# M367 register map
File version: 0.1
CPU: 
Registers are 32-bit, read-write, reset 0x0 unless marked. A register's access mark holds for its fields unless they carry their own. Offsets are from the block's base; [hi:lo] are bit positions; {n}, {i} and the like mark numbered series; 'fields as' and 'values as' point back to an identical list.

## UDFS2 — UDC2(USB -Spec2.0 Device contoller)
Base 0x40008200
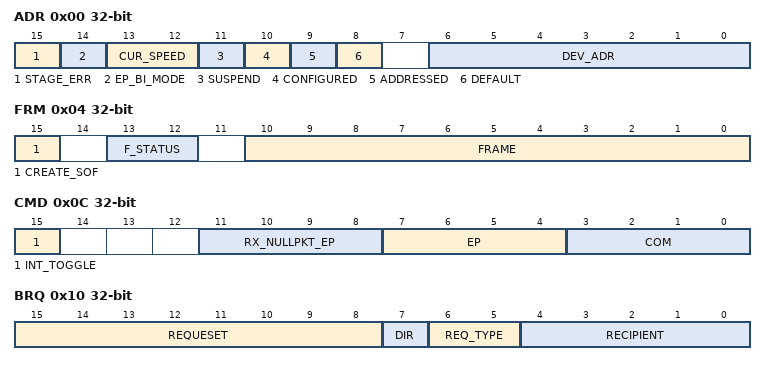
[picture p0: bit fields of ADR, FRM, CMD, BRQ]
0x00 ADR — UDC2 Address State
  [15] STAGE_ERR, [14] EP_BI_MODE, [13:12] CUR_SPEED ro, [11] SUSPEND ro, [10] CONFIGURED, [9] ADDRESSED, [8] DEFAULT, [6:0] DEV_ADR
0x04 FRM — UDC2 Frame
  [15] CREATE_SOF, [13:12] F_STATUS ro, [10:0] FRAME ro
0x0C CMD — UDC2 Command
  [15] INT_TOGGLE, [11:8] RX_NULLPKT_EP ro, [7:4] EP, [3:0] COM
0x10 BRQ ro — UDC2 bRequest-bmRequest Type
  [15:8] REQUESET, [7] DIR, [6:5] REQ_TYPE, [4:0] RECIPIENT
0x14 WVL ro — UDC2 wValue
  [15:0] VALUE
0x18 WIDX ro — UDC2 wIndex
  [15:0] INDEX
0x1C WLGTH ro — UDC2 wLength
  [15:0] LENGTH
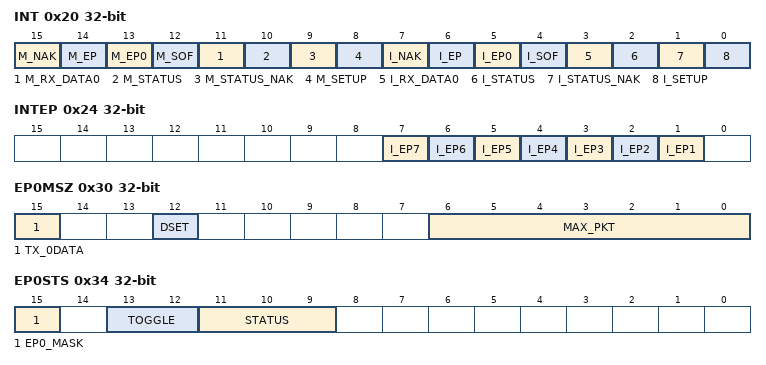
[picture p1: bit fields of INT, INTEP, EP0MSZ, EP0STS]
0x20 INT — UDC2 INT
  [15] M_NAK, [14] M_EP, [13] M_EP0, [12] M_SOF, [11] M_RX_DATA0, [10] M_STATUS, [9] M_STATUS_NAK, [8] M_SETUP, [7] I_NAK, [6] I_EP, [5] I_EP0, [4] I_SOF, [3] I_RX_DATA0, [2] I_STATUS, [1] I_STATUS_NAK, [0] I_SETUP
0x24 INTEP — UDC2 INT_EP
  [n] I_EP{n} (n=1..7)
0x28 INTEPMSK — UDC2 INT_EP_MASK
  [7:0] M_EP
0x2C INTRX0 — UDC2 INT RX DATA0
  [7:0] RX_D0_EP
0x30 EP0MSZ — UDC2 EP0 Max Packet Size
  [15] TX_0DATA ro, [12] DSET ro, [6:0] MAX_PKT
0x34 EP0STS ro — UDC2 EP0 Status
  [15] EP0_MASK, [13:12] TOGGLE, [11:9] STATUS
0x38 EP0DSZ ro — UDC2 EP0 Data Size
  [6:0] SIZE
{0x3C+0x10*i} EP{i}FIFO (i=0..2) — UDC2 EP{i} FIFO
  [15:0] DATA
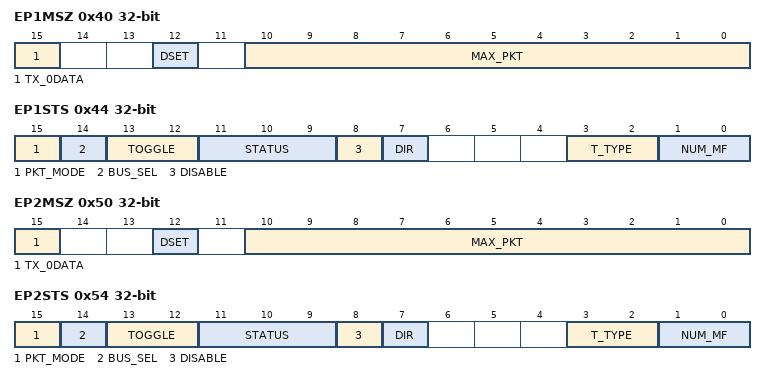
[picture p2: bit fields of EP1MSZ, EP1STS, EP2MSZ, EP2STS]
0x40 EP1MSZ — UDC2 EP1 Max Packet Size
  [15] TX_0DATA ro, [12] DSET ro, [10:0] MAX_PKT
0x44 EP1STS — UDC2 EP1 Status
  [15] PKT_MODE, [14] BUS_SEL, [13:12] TOGGLE ro, [11:9] STATUS ro, [8] DISABLE ro, [7] DIR, [3:2] T_TYPE, [1:0] NUM_MF
0x48 EP1DSZ ro — UDC2 EP1 Data Size
  [10:0] SIZE
0x50 EP2MSZ — UDC2 EP2 Max Packet Size
  [15] TX_0DATA ro, [12] DSET ro, [10:0] MAX_PKT
0x54 EP2STS — UDC2 EP2 Status
  fields as EP1STS
0x58 EP2DSZ ro — UDC2 EP2 Data Size
  [10:0] SIZE
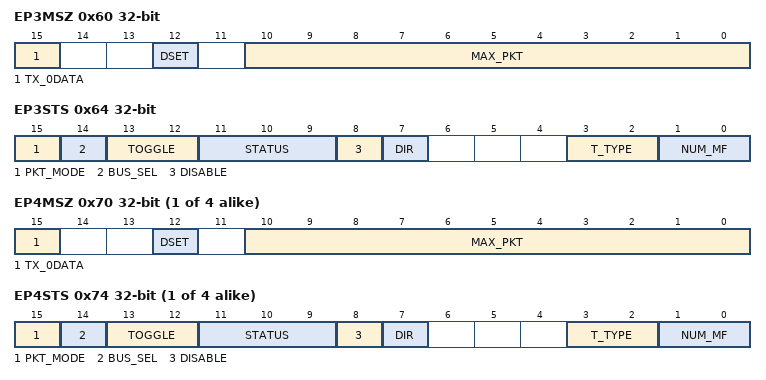
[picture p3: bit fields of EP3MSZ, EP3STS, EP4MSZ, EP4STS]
0x60 EP3MSZ — UDC3 EP3 Max Packet Size
  [15] TX_0DATA ro, [12] DSET ro, [10:0] MAX_PKT
0x64 EP3STS — UDC3 EP3 Status
  fields as EP1STS
0x68 EP3DSZ ro — UDC3 EP3 Data Size
  [10:0] SIZE
0x6C EP3FIFO — UDC3 EP3 FIFO
  [15:0] DATA
{0x30+0x10*i} EP{i}MSZ (i=4..7) — UDC2 EP{i} Max Packet Size
  [15] TX_0DATA ro, [12] DSET ro, [10:0] MAX_PKT
{0x34+0x10*i} EP{i}STS (i=4..7) — UDC2 EP{i} Status
  fields as EP1STS
{0x38+0x10*i} EP{i}DSZ ro (i=4..7) — UDC2 EP{i} Data Size
  [10:0] SIZE
{0x3C+0x10*i} EP{i}FIFO (i=4..7) — UDC2 EP{i} FIFO
  [15:0] DATA
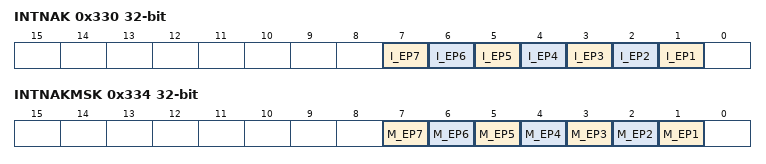
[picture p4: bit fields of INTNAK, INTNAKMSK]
0x330 INTNAK — UDC2 INT NAK
  [n] I_EP{n} (n=1..7)
0x334 INTNAKMSK — UDC2 INT NAK MASK
  [n] M_EP{n} (n=1..7)

## SSP0 — Synchronous Serial Port
Base 0x40040000
Same registers: SSP1 0x40041000, SSP2 0x40042000
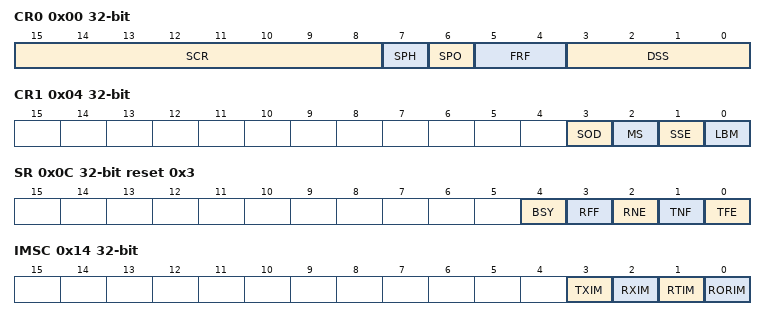
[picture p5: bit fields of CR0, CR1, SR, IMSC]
0x00 CR0 — SSP Control Register 0
  [15:8] SCR, [7] SPH, [6] SPO, [5:4] FRF, [3:0] DSS
0x04 CR1 — SSP Control Register 1
  [3] SOD, [2] MS, [1] SSE, [0] LBM
0x08 DR — SSP Data Register
  [15:0] DATA
0x0C SR ro reset 0x3 — SSP Status Register
  [4] BSY, [3] RFF, [2] RNE, [1] TNF, [0] TFE
0x10 CPSR — SSP Clock Prescaler Register
  [7:0] CPSDVSR
0x14 IMSC — SSP Interrupt Mask Set and Clear Register
  [3] TXIM, [2] RXIM, [1] RTIM, [0] RORIM
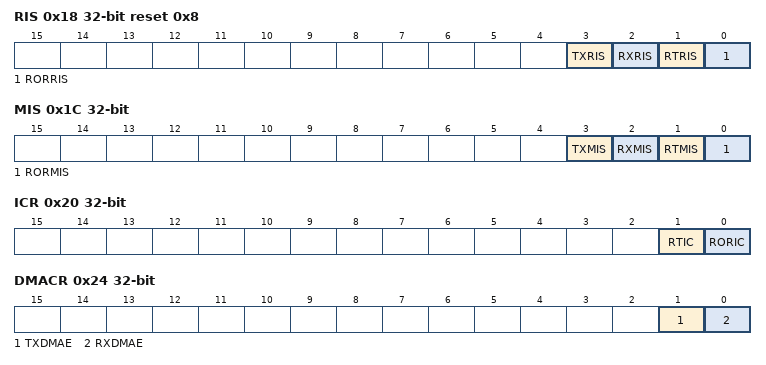
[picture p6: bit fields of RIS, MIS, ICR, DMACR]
0x18 RIS ro reset 0x8 — SSP Raw Interrupt Status Register
  [3] TXRIS, [2] RXRIS, [1] RTRIS, [0] RORRIS
0x1C MIS ro — SSP Masked Interrupt Status Register
  [3] TXMIS, [2] RXMIS, [1] RTMIS, [0] RORMIS
0x20 ICR wo reset not defined — SSP Interrupt Clear Register
  [1] RTIC, [0] RORIC
0x24 DMACR — SSP DMA Control Register
  [1] TXDMAE, [0] RXDMAE

## UART4 — ARM Prime Cell PL011
Base 0x40048000
Same registers: UART5 0x40049000
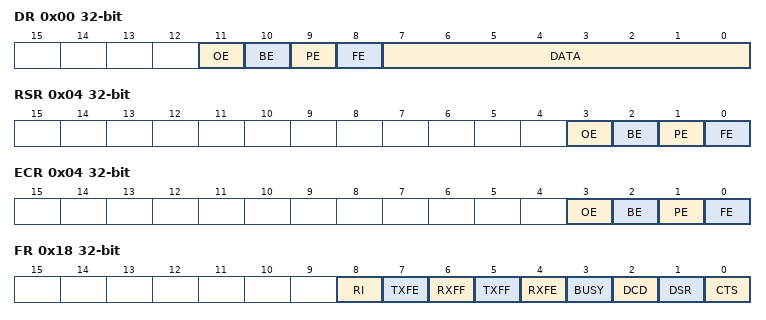
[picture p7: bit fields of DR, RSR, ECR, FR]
0x00 DR — Data Register
  [11] OE, [10] BE, [9] PE, [8] FE, [7:0] DATA
0x04 RSR ro — Receive Status Register
  [3] OE, [2] BE, [1] PE, [0] FE
0x04 ECR wo — Error Clear Register
  [3] OE, [2] BE, [1] PE, [0] FE
0x18 FR — Flag Register
  [8] RI, [7] TXFE, [6] RXFF, [5] TXFF, [4] RXFE, [3] BUSY, [2] DCD, [1] DSR, [0] CTS
0x20 ILPR — IrDA Low-power Counter register
  [7:0] ILPDVSR
0x24 IBDR — Integer Baud Rate Register
  [15:0] BAUDDIVINT
0x28 FBDR — Fractional Baud Rate Register
  [5:0] BAUDDIVFRAC
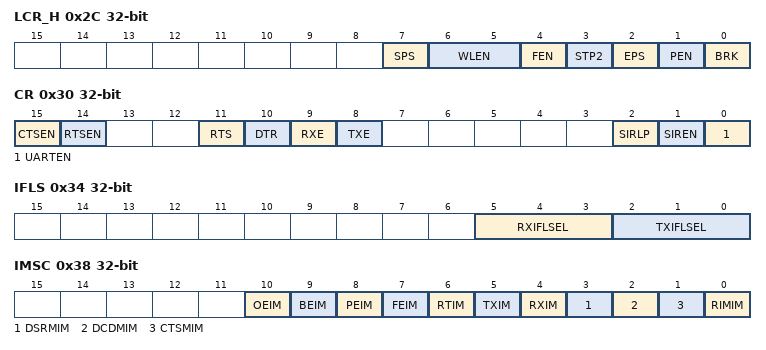
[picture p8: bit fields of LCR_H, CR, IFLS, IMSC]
0x2C LCR_H — Line Control Register
  [7] SPS, [6:5] WLEN, [4] FEN, [3] STP2, [2] EPS, [1] PEN, [0] BRK
0x30 CR — Cntrol Register
  [15] CTSEN, [14] RTSEN, [11] RTS, [10] DTR, [9] RXE, [8] TXE, [2] SIRLP, [1] SIREN, [0] UARTEN
0x34 IFLS — Interrupt FIFO Level Select Register
  [5:3] RXIFLSEL, [2:0] TXIFLSEL
0x38 IMSC — Interrupt Mask set_Clear Register
  [10] OEIM, [9] BEIM, [8] PEIM, [7] FEIM, [6] RTIM, [5] TXIM, [4] RXIM, [3] DSRMIM, [2] DCDMIM, [1] CTSMIM, [0] RIMIM
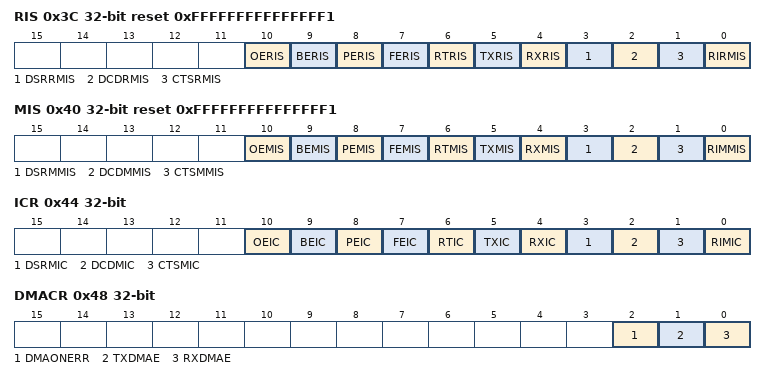
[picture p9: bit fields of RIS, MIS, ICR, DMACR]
0x3C RIS ro reset 0xFFFFFFFFFFFFFFF1 — Raw Interrupt Status Register
  [10] OERIS, [9] BERIS, [8] PERIS, [7] FERIS, [6] RTRIS, [5] TXRIS, [4] RXRIS, [3] DSRRMIS, [2] DCDRMIS, [1] CTSRMIS, [0] RIRMIS
0x40 MIS ro reset 0xFFFFFFFFFFFFFFF1 — Masked Interrupt Status Register
  [10] OEMIS, [9] BEMIS, [8] PEMIS, [7] FEMIS, [6] RTMIS, [5] TXMIS, [4] RXMIS, [3] DSRMMIS, [2] DCDMMIS, [1] CTSMMIS, [0] RIMMIS
0x44 ICR wo — Interrupt Clear Register
  [10] OEIC, [9] BEIC, [8] PEIC, [7] FEIC, [6] RTIC, [5] TXIC, [4] RXIC, [3] DSRMIC, [2] DCDMIC, [1] CTSMIC, [0] RIMIC
0x48 DMACR — DMA Control Register
  [2] DMAONERR, [1] TXDMAE, [0] RXDMAE
